# SAM9X75D1G device description
Architecture: ARM926EJ-S; Family: SAM9; Series: SAM9X7
Registers are 32-bit, read-write, reset 0x0 unless marked. A register's access mark holds for its fields unless they carry their own. Offsets are from the block's base; [hi:lo] are bit positions; {n}, {i} and the like mark numbered series.

## QSPI — Quad Serial Peripheral Interface
Instances: QSPI 0xF0014000
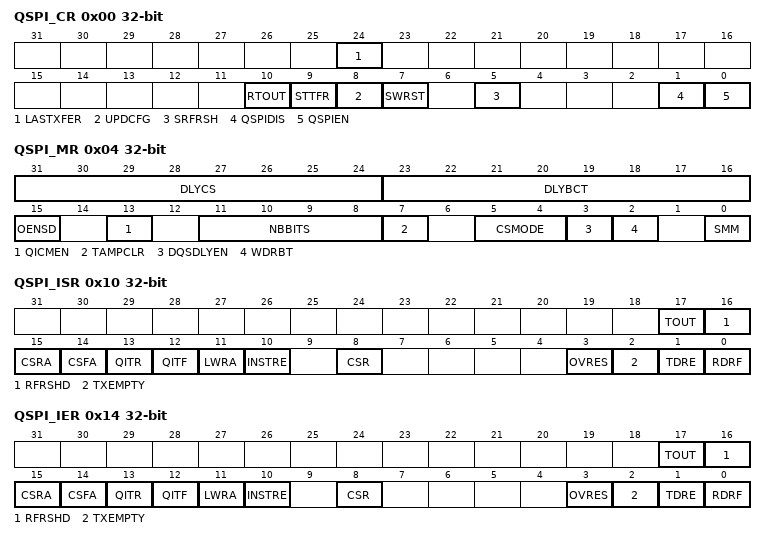
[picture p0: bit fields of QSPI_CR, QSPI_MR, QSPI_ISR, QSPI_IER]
0x00 QSPI_CR wo reset not defined — Control Register
  [24] LASTXFER — Last Transfer
    0=No effect; 1=The chip select is deasserted after the end of character transmission
  [10] RTOUT — Reset Time-out
    0=No effect; 1=Request a TOUT flag reset
  [9] STTFR — Start Transfer
    0=No effect; 1=Starts the transfer when TFRTYP = 0 and SMRM = 1 or when DATAEN = 0
  [8] UPDCFG — Update Configuration
    0=No effect; 1=Requests an update of the QSPI Controller core configuration
  [7] SWRST — QSPI Software Reset
    0=No effect; 1=Resets the QSPI. A software-triggered hardware reset of the QSPI interface is performed.
  [5] SRFRSH — Start REFRESH
    0=No effect; 1=Starts a refresh sequence. QSPI_ISR.RFRSHD indicates when the refresh sequence is over.
  [1] QSPIDIS — QSPI Disable
    0=No effect; 1=Disables the QSPI
  [0] QSPIEN — QSPI Enable
    0=No effect; 1=Enables the QSPI to transfer and receive data
0x04 QSPI_MR — Mode Register
  [31:24] DLYCS — Minimum Inactive QCS Delay
  [23:16] DLYBCT — Delay Between Consecutive Transfers
  [15] OENSD — Output Enable Shift Disabled
    0=By default, the pad output enable signal is held for one QSCK period during the dummy cycles if QSPI.IFR_NBDUM is not equal to '0'; 1=The pad output enable signal is not held for one QSCK period during the dummy cycles
  [13] QICMEN — QSPI Inter-chip Mode Enable
    0=DISABLED (QSPI_WICR.WROPT and QSPI_RICR.RDOPT define the transfer options and QSPI_IFR.NBDUM defines the number of dummy cycles.); 1=ENABLED (No dummy cycles are inserted for write accesses, whatever the value configured in QSPI_IFR.NBDUM. The option field of the frame is automatically generated by the QSPI depending on the type of system bus transfer (the fields QSPI_RICR.RDOPT and QSPI_WICR.WROPT have no effect).)
  [11:8] NBBITS — Number Of Bits Per Transfer
    0=8_BIT (8 bits for transfer); 8=16_BIT (16 bits for transfer)
  [7] TAMPCLR — Tamper Clear Enable
    0=A tamper detection event has no effect on QSPI scrambling keys; 1=A tamper detection event immediately clears QSPI scrambling keys
  [5:4] CSMODE — Chip Select Mode
    0=NOT_RELOADED (The chip select is deasserted if QSPI_TDR.TD has not been reloaded before the end of the current transfer.); 1=LASTXFER (The chip select is deasserted when the bit LASTXFER is written to '1' and the character written in QSPI_TDR.TD has been transferred.); 2=SYSTEMATICALLY (The chip select is deasserted systematically after each transfer.)
  [3] DQSDLYEN — DQS Delay Enable
    0=DISABLED (DQS Delay cell is disabled.); 1=ENABLED (DQS Delay cell is enabled. The DQS Delay cell automatic refresh is triggered according to the configuration of QSPI_REFRESH.)
  [2] WDRBT — Wait Data Read Before Transfer
    0=DISABLED (No effect. In SPI mode, a transfer can be initiated whatever the state of QSPI_RDR is.); 1=ENABLED (In SPI mode, a transfer can start only if QSPI_RDR is empty, i.e., does not contain any unread data. This mode prevents overrun error in reception.)
  [0] SMM — Serial Memory Mode
    0=SPI (The QSPI is in SPI mode.); 1=MEMORY (The QSPI is in Serial Memory mode.)
0x08 QSPI_RDR ro — Receive Data Register
  [15:0] RD — Receive Data
0x0C QSPI_TDR wo reset not defined — Transmit Data Register
  [15:0] TD — Transmit Data
0x10 QSPI_ISR ro — Interrupt Status Register
  [17] TOUT — QSPI Time-out
    0=No QSPI time-out occurred since the last write of RTOUT bit on QSPI_CR; 1=At least one QSPI time-out occurred since the last write of RTOUT bit on QSPI_CR
  [16] RFRSHD — Refresh Done
    0=No refresh done event occurred since the last read of QSPI_ISR; 1=One refresh done event has been detected since the end of the last refresh command or the last read of QSPI_ISR
  [15] CSRA — Chip Select Rise Autoclear
    0=No chip select rise has been detected since beginning of the last command or the last read of QSPI_ISR; 1=One chip select rise has been detected since the beginning of the last command or the last read of QSPI_ISR
  [14] CSFA — Chip Select Fall Autoclear
    0=No chip select fall has been detected since end of the last command or the last read of QSPI_ISR; 1=One chip select fall has been detected since the end of the last command or the last read of QSPI_ISR
  [13] QITR — QSPI Interrupt Rise
    0=No rising of the QSPI memory interrupt line has been detected since the last read of QSPI_ISR; 1=At least one QSPI memory interrupt line rising edge occurred since the last read of QSPI_ISR
  [12] QITF — QSPI Interrupt Fall
    0=No falling of the QSPI memory interrupt line has been detected since the last read of QSPI_ISR; 1=At least one QSPI memory interrupt line falling edge occurred since the last read of QSPI_ISR
  [11] LWRA — Last Write Access (cleared on read)
    0=Last write access has not been sent since the last read of QSPI_SR or NBWRA = 0; 1=At least one last write access has been sent since the last read of QSPI_SR
  [10] INSTRE — Instruction End Status (cleared on read)
    0=No instruction end has been detected since the last read of QSPI_SR; 1=At least one instruction end has been detected since the last read of QSPI_SR
  [8] CSR — Chip Select Rise (cleared on read)
    0=No chip select rise has been detected since the last read of QSPI_SR; 1=At least one chip select rise has been detected since the last read of QSPI_SR
  [3] OVRES — Overrun Error Status (cleared on read)
    0=No overrun has been detected since the last read of QSPI_ISR; 1=At least one overrun error has occurred since the last read of QSPI_ISR
  [2] TXEMPTY — Transmission Registers Empty (cleared by writing QSPI_TDR)
    0=As soon as data is written in QSPI_TDR; 1=QSPI_TDR and the internal shifter are empty. If a transfer delay has been defined, TXEMPTY is set after the completion of such delay.
  [1] TDRE — Transmit Data Register Empty (cleared by writing QSPI_TDR)
    0=Data has been written to QSPI_TDR and not yet transferred to the serializer; 1=The last data written in the QSPI_TDR has been transferred to the serializer
  [0] RDRF — Receive Data Register Full (cleared by reading QSPI_RDR)
    0=No data has been received since the last read of QSPI_RDR; 1=Data has been received and the received data has been transferred from the serializer to QSPI_RDR since the last read of QSPI_RDR
0x14 QSPI_IER wo reset not defined (atomic set of QSPI_IMR) — Interrupt Enable Register
  [17] TOUT — QSPI Time-out Interrupt Enable
  [16] RFRSHD — Refresh Done Interrupt Enable
  [15] CSRA — Chip Select Rise Autoclear Interrupt Enable
  [14] CSFA — Chip Select Fall Autoclear Interrupt Enable
  [13] QITR — QSPI Interrupt Rise Interrupt Enable
  [12] QITF — QSPI Interrupt Fall Interrupt Enable
  [11] LWRA — Last Write Access Interrupt Enable
  [10] INSTRE — Instruction End Interrupt Enable
  [8] CSR — Chip Select Rise Interrupt Enable
  [3] OVRES — Overrun Error Interrupt Enable
  [2] TXEMPTY — Transmission Registers Empty Enable
  [1] TDRE — Transmit Data Register Empty Interrupt Enable
  [0] RDRF — Receive Data Register Full Interrupt Enable
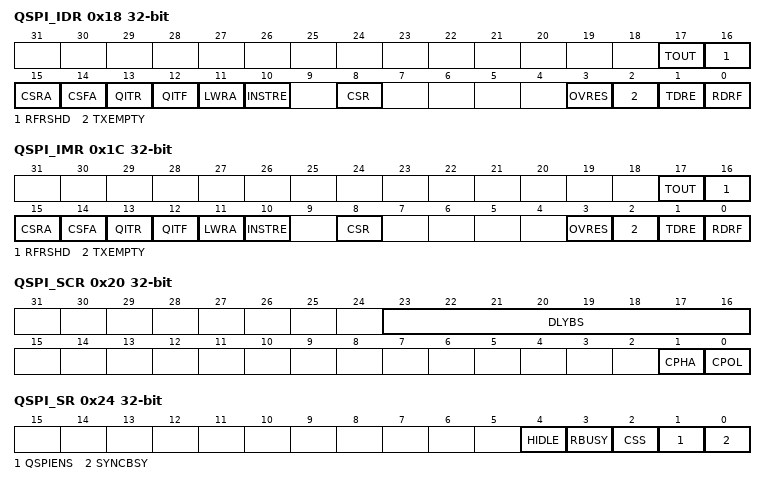
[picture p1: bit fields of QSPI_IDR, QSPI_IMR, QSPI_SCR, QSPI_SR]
0x18 QSPI_IDR wo reset not defined (atomic clear of QSPI_IMR) — Interrupt Disable Register
  [17] TOUT — QSPI Time-out Interrupt Disable
  [16] RFRSHD — Refresh Done Interrupt Disable
  [15] CSRA — Chip Select Rise Autoclear Interrupt Disable
  [14] CSFA — Chip Select Fall Autoclear Interrupt Disable
  [13] QITR — QSPI Interrupt Rise Interrupt Disable
  [12] QITF — QSPI Interrupt Fall Interrupt Disable
  [11] LWRA — Last Write Access Interrupt Disable
  [10] INSTRE — Instruction End Interrupt Disable
  [8] CSR — Chip Select Rise Interrupt Disable
  [3] OVRES — Overrun Error Interrupt Disable
  [2] TXEMPTY — Transmission Registers Empty Disable
  [1] TDRE — Transmit Data Register Empty Interrupt Disable
  [0] RDRF — Receive Data Register Full Interrupt Disable
0x1C QSPI_IMR ro — Interrupt Mask Register
  [17] TOUT — QSPI Time-out Interrupt Mask
  [16] RFRSHD — Refresh Done Interrupt Mask
  [15] CSRA — Chip Select Rise Autoclear Interrupt Mask
  [14] CSFA — Chip Select Fall Autoclear Interrupt Mask
  [13] QITR — QSPI Interrupt Rise Interrupt Mask
  [12] QITF — QSPI Interrupt Fall Interrupt Mask
  [11] LWRA — Last Write Access Interrupt Mask
  [10] INSTRE — Instruction End Interrupt Mask
  [8] CSR — Chip Select Rise Interrupt Mask
  [3] OVRES — Overrun Error Interrupt Mask
  [2] TXEMPTY — Transmission Registers Empty Mask
  [1] TDRE — Transmit Data Register Empty Interrupt Mask
  [0] RDRF — Receive Data Register Full Interrupt Mask
0x20 QSPI_SCR (atomic clear of QSPI_SR) — Serial Clock Register
  [23:16] DLYBS — Delay Before QSCK
  [1] CPHA — Clock Phase
    0=Data is captured on the leading edge of QSCK and changed on the following edge of QSCK; 1=Data is changed on the leading edge of QSCK and captured on the following edge of QSCK
  [0] CPOL — Clock Polarity
    0=The inactive state value of QSCK is logic level zero; 1=The inactive state value of QSCK is logic level one
0x24 QSPI_SR — Status Register
  [4] HIDLE — QSPI Idle
    0=The QSPI is not in Idle state (either transmitting or Chip Select is active); 1=The QSPI is in Idle state (not transmitting and Chip Select is inactive)
  [3] RBUSY — Read Busy
    0=The system bus interface has no activity; 1=The system bus interface is currently processing accesses
  [2] CSS — Chip Select Status
    0=The chip select is asserted; 1=The chip select is not asserted
  [1] QSPIENS — QSPI Enable Status
    0=The QSPI is disabled; 1=The QSPI is enabled
  [0] SYNCBSY — Synchronization Busy
    0=No event synchronization between the QSPI Controller interface and QSPI Controller core is ongoing. Register accesses requiring synchronization are allowed, see Register Synchronization.; 1=Event synchronization between the QSPI Controller interface and QSPI Controller core is ongoing. Register accesses requiring synchronization are not allowed, see Register Synchronization.
0x30 QSPI_IAR — Instruction Address Register
  [31:0] ADDR — Address
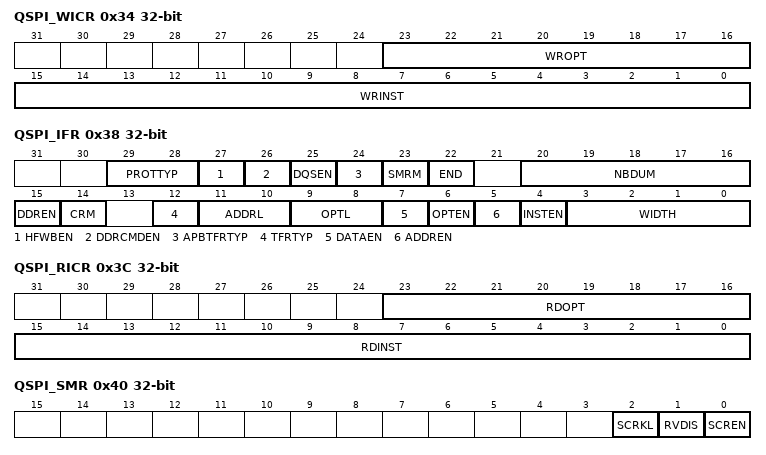
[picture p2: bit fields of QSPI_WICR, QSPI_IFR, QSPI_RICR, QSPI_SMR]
0x34 QSPI_WICR — Write Instruction Code Register
  [23:16] WROPT — Write Option Code
  [15:0] WRINST — Write Instruction Code
0x38 QSPI_IFR — Instruction Frame Register
  [29:28] PROTTYP — Protocol Type
    0=STD_SPI (Standard (Q)SPI Protocol); 1=TWIN_QUAD (Twin-Quad Protocol); 2=OCTAFLASH (OctaFlash Protocol); 3=HYPERFLASH (HyperFlash Protocol)
  [27] HFWBEN — HyperFlash Write Buffer Enable
    0=No effect; 1=Each write access received on the system bus interface generates a new command. IMPORTANT: Mandatory if HyperFlash Write Buffer feature is used.
  [26] DDRCMDEN — DDR Mode Command Enable
    0=DISABLED (Transfer of instruction field is performed in Single Data Rate mode even if DDREN is written to '1'.); 1=ENABLED (Transfer of instruction field is performed in Double Data Rate mode if DDREN bit is written to '1'. If DDREN is written to '0', the instruction field is sent in Single Data Rate mode.)
  [25] DQSEN — DQS Sampling Enable
    0=Data from the memory are not sampled with DQS signal; 1=Data from the memory are sampled with DQS signal
  [24] APBTFRTYP — Peripheral BusTransfer Type
    0=Peripheral bus register transfer to the memory is a write transfer. Used when TRFTYP is written to '0' and SMRM to '1'.; 1=Peripheral bus register transfer to the memory is a read transfer. Used when TRFTYP is written to '0' and SMRM to '1'.
  [23] SMRM — Serial Memory Register Mode
    0=Serial Memory registers are written via AHB access. See Instruction Frame Transmission for details.; 1=Serial Memory registers are written via APB access. See Instruction Frame Transmission for details.
  [22] END — Endianness
    0=Data are sent in little-endian format to the memory; 1=Data are sent in big-endian format to the memory
  [20:16] NBDUM — Number Of Dummy Cycles
  [15] DDREN — DDR Mode Enable
    0=DISABLED (Transfers are performed in Single Data Rate mode.); 1=ENABLED (Transfers are performed in Double Data Rate mode, whereas the instruction field is still transferred in Single Data Rate mode.)
  [14] CRM — Continuous Read Mode
    0=DISABLED (Continuous Read mode is disabled.); 1=ENABLED (Continuous Read mode is enabled.)
  [12] TFRTYP — Data Transfer Type
    0=TRSFR_REGISTER (Read/Write of memory register, write of memory page buffer. This configuration implies the following: Either the AHB or the APB interface can be used to initiate the transfer (SMRM bit). Returned data represents the memory register value. If the APB interface is used, the RDRF and TDRE flags help to control the frame. Scrambling is possible only if the APB interface is used. For HyperFlash memories the "target" bit is set to register space in the HyperFlash header.); 1=TRSFR_MEMORY (Read/Write accesses to the memory space. This configuration implies the following: Only the System Bus interface can be used to trigger accesses. Access to random location is possible. Address mask is applied and full size accesses only are performed. Internal optimization algorithm is enabled to minimize latency. Data are returned in a system bus protocol compliant way. Seamless scrambling is enabled. Seamless handling of HyperFlash Write Buffer programming command (one command for each data) Seamless protocol-specific page boundary handling Address shift is handled seamlessly (e.g. halfword memories).)
  [11:10] ADDRL — Address Length
    0=8_BIT (8-bit address size); 1=16_BIT (16-bit address size); 2=24_BIT (24-bit address size); 3=32_BIT (32-bit address size)
  [9:8] OPTL — Option Code Length
    0=OPTION_1BIT (The option code is 1 bit long.); 1=OPTION_2BIT (The option code is 2 bits long.); 2=OPTION_4BIT (The option code is 4 bits long.); 3=OPTION_8BIT (The option code is 8 bits long.)
  [7] DATAEN — Data Enable
    0=No data is sent/received to/from the serial Flash memory; 1=Data is sent/received to/from the serial Flash memory
  [6] OPTEN — Option Enable
    0=The option is not sent to the serial Flash memory; 1=The option is sent to the serial Flash memory
  [5] ADDREN — Address Enable
    0=The transfer address is not sent to the serial Flash memory; 1=The transfer address is sent to the serial Flash memory
  [4] INSTEN — Instruction Enable
    0=The instruction is not sent to the serial Flash memory; 1=The instruction is sent to the serial Flash memory
  [3:0] WIDTH — Width of Instruction Code, Address, Option Code and Data
    0=SINGLE_BIT_SPI (Instruction: Single-bit SPI / Address-Option: Single-bit SPI / Data: Single-bit SPI); 1=DUAL_OUTPUT (Instruction: Single-bit SPI / Address-Option: Single-bit SPI / Data: Dual SPI); 2=QUAD_OUTPUT (Instruction: Single-bit SPI / Address-Option: Single-bit SPI / Data: Quad SPI); 3=DUAL_IO (Instruction: Single-bit SPI / Address-Option: Dual SPI / Data: Dual SPI); 4=QUAD_IO (Instruction: Single-bit SPI / Address-Option: Quad SPI / Data: Quad SPI); 5=DUAL_CMD (Instruction: Dual SPI / Address-Option: Dual SPI / Data: Dual SPI); 6=QUAD_CMD (Instruction: Quad SPI / Address-Option: Quad SPI / Data: Quad SPI); 7=OCT_OUTPUT (Instruction: Single-bit SPI / Address-Option: Single-bit SPI / Data: Octal SPI); 8=OCT_IO (Instruction: Single-bit SPI / Address-Option: Octal SPI / Data: Octal SPI); 9=OCT_CMD (Instruction: Octal SPI / Address-Option: Octal SPI / Data: Octal SPI)
0x3C QSPI_RICR — Read Instruction Code Register
  [23:16] RDOPT — Read Option Code
  [15:0] RDINST — Read Instruction Code
0x40 QSPI_SMR — Scrambling Mode Register
  [2] SCRKL — Scrambling Key Lock
    0=No action; 1=QSPI_SKR.USRK cannot be written until the next VDDCORE reset
  [1] RVDIS — Scrambling/Unscrambling Random Value Disable
    0=The scrambling/unscrambling algorithm includes the user scrambling key plus a random value that may differ between devices; 1=The scrambling/unscrambling algorithm includes only the user scrambling key
  [0] SCREN — Scrambling/Unscrambling Enable
    0=DISABLED (The scrambling/unscrambling is disabled.); 1=ENABLED (The scrambling/unscrambling is enabled.)
0x44 QSPI_SKR wo reset not defined — Scrambling Key Register
  [31:0] USRK — User Scrambling Key
0x50 QSPI_REFRESH — Refresh Register
  [31:0] REFRESH — REFRESH Delay Counter
0x54 QSPI_WRACNT — Write Access Counter Register
  [31:0] NBWRA — Number of Write Accesses
0x5C QSPI_PCALCFG reset 0x70 — Pad Calibration Configuration Register
  [2] DIFFPM — Differential Pad Mode
    0=Pad differential mode is not enabled; 1=Pad differential mode is enabled
0x64 QSPI_TOUT — Timeout Register
  [15:0] TCNTM — Time-out Counter Maximum Value
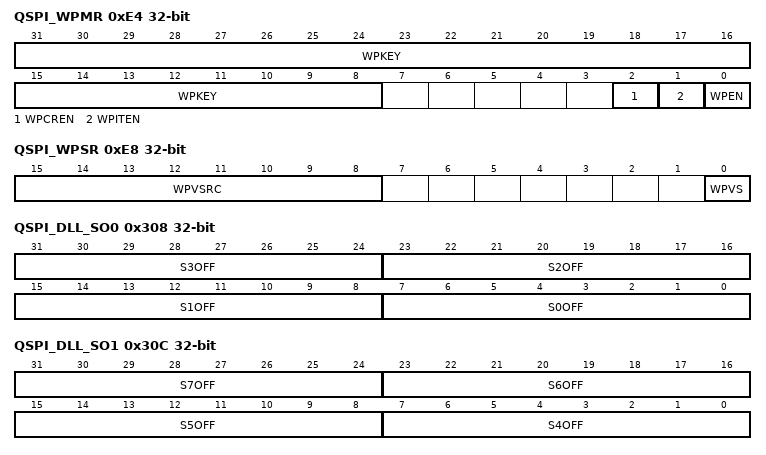
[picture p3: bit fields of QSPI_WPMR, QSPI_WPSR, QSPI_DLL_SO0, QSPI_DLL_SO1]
0xE4 QSPI_WPMR — Write Protection Mode Register
  [31:8] WPKEY — Write Protection Key
    0x515350=PASSWD (Writing any other value in this field aborts the write operation of the WPEN bit. Always reads as 0.)
  [2] WPCREN — Write Protection Control Register Enable
    0=Disables the write protection on the Control register if WPKEY corresponds to 0x515350; 1=Enables the write protection on the Control register if WPKEY corresponds to 0x515350
  [1] WPITEN — Write Protection Interrupt Enable
    0=Disables the write protection on Interrupt registers if WPKEY corresponds to 0x515350; 1=Enables the write protection on Interrupt registers if WPKEY corresponds to 0x515350
  [0] WPEN — Write Protection Enable
    0=Disables the write protection if WPKEY corresponds to 0x515350 ("QSP" in ASCII); 1=Enables the write protection if WPKEY corresponds to 0x515350 ("QSP" in ASCII)
0xE8 QSPI_WPSR ro — Write Protection Status Register
  [15:8] WPVSRC — Write Protection Violation Source
  [0] WPVS — Write Protection Violation Status
    0=No write protection violation has occurred since the last read of the QSPI_WPSR; 1=A write protection violation has occurred since the last read of the QSPI_WPSR. If this violation is an unauthorized attempt to write a protected register, the associated violation is reported into field WPVSRC.
0x300 QSPI_DLL_OS — QSPI DLL Offset Selection Register
  [0] SELOFF — Offset Selection
    0=The hardcoded offsets are selected; 1=The programmable offsets are selected
0x304 QSPI_DLL_MAO — QSPI DLL Host Offset Register
  [7:0] MAOFF — Host Delay Line Offset
0x308 QSPI_DLL_SO0 — QSPI DLL Client Offset 0 Register
  [8n+7:8n] S{n}OFF (n=0..3) — SLAVEx Delay Line Offset
0x30C QSPI_DLL_SO1 — QSPI DLL Client Offset 1 Register
  [8n-25:8n-32] S{n}OFF (n=4..7) — SLAVEx Delay Line Offset
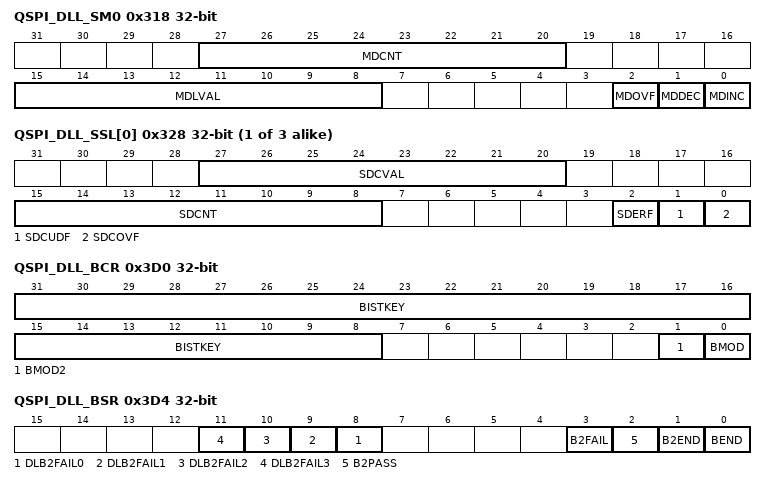
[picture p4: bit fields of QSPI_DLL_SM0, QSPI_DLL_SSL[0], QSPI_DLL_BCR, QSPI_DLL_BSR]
0x318 QSPI_DLL_SM0 ro — QSPI DLL Status Host 0 Register
  [27:20] MDCNT — MASTER0 Delay Counter Value
  [15:8] MDLVAL — MASTER0 Delay Lock Value
  [2] MDOVF — MASTER0 Delay Overflow Flag
    0=The MASTER0 delay counter has not reached its maximum value, or MASTER0 is not locked yet; 1=The MASTER0 delay counter has reached its maximum value, the MASTER0 delay counter increment is stopped and the DQSDELAY forces the MASTER0 clock. If this flag is set, it means the DDR-SDRAM controller clock frequency is too low compared to MASTER0 delay line number of elements.
  [1] MDDEC — MASTER0 Delay Decrement
    0=The DQSDELAY is not decrementing the MASTER0 delay counter; 1=The DQSDELAY is decrementing the MASTER0 delay counter
  [0] MDINC — MASTER0 Delay Increment
    0=The DQSDELAY is not incrementing the MASTER0 delay counter; 1=The DQSDELAY is incrementing the MASTER0 delay counter
{0x328+4i} QSPI_DLL_SSL[{i}] (i=0..2) ro — QSPI DLL Status Client x Register
  [27:20] SDCVAL — SLAVE0 Delay Correction Value
  [15:8] SDCNT — SLAVE0 Delay Counter Value
  [2] SDERF — SLAVE0 Delay Correction Error Flag
    0=The DQSDELAY has succeeded in computing the SLAVE0 delay correction, or the client is not locked yet; 1=The DQSDELAY has not succeeded in computing the SLAVE0 delay correction
  [1] SDCUDF — SLAVE0 Delay Correction Underflow Flag
    0=Due to the correction, the SLAVE0 delay counter has not reached its minimum value, or SLAVE0 is not locked yet; 1=Due to the correction, the SLAVE0 delay counter has reached its minimum value. The correction is not optimal because it has not been applied entirely.
  [0] SDCOVF — SLAVE0 Delay Correction Overflow Flag
    0=Due to the correction, the SLAVE0 delay counter has not reached its maximum value, or SLAVE0 is not locked yet; 1=Due to the correction, the SLAVE0 delay counter has reached its maximum value. The correction is not optimal because it is not applied entirely.
0x3D0 QSPI_DLL_BCR — QSPI DLL BIST Control Register
  [31:8] BISTKEY
    0xDD3313=VALUE (Write to 0xDD3313 to enable modification of BMOD or BMOD2 state.)
  [1] BMOD2 — BIST Mode 2
  [0] BMOD — BIST Mode
0x3D4 QSPI_DLL_BSR ro — QSPI DLL BIST Status Register
  [n+8] DLB2FAIL{n} (n=0..3) — Delay Line BIST 2 Fail for Delay Line {n}
    0=The BIST 2 test did not fail; 1=The BIST 2 test failed for delay line x
  [3] B2FAIL — BIST 2 Fail
    0=The BIST 2 test has not finished or succeeded; 1=The BIST 2 test failed. Check DLB2FAILx bits to identify the corrupted delay lines.
  [2] B2PASS — BIST 2 Pass
    0=The BIST 2 test has not finished or failed; 1=The BIST 2 test ended successfully
  [1] B2END — BIST 2 End
    0=BIST 2 test has not started or in progress; 1=BIST 2 test is finished
  [0] BEND — BIST End
    0=BIST test has not started or is in progress; 1=BIST test is finished
0x3E0 QSPI_DLL_SYNCR — QSPI DLL Synchro Register
  [0] UPDT — Update configuration
    0=No effect; 0=Configuration is up to date; 1=Initiates the configuration update; 1=Configuration is being updated
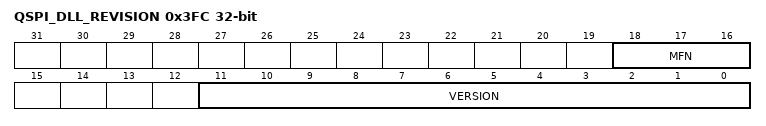
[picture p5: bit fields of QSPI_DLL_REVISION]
0x3FC QSPI_DLL_REVISION ro — QSPI DQSDELAY Revision Register
  [18:16] MFN — Metal Fix Number
  [11:0] VERSION — Hardware Module Version

## Notices in the file
Copyright (c) 2021 Microchip Technology Inc.
SPDX-License-Identifier: Apache-2.0
Licensed under the Apache License, Version 2.0 (the "License");
you may not use this file except in compliance with the License.
You may obtain a copy of the License at
http://www.apache.org/licenses/LICENSE-2.0
Unless required by applicable law or agreed to in writing, software
distributed under the License is distributed on an "AS IS" BASIS,
WITHOUT WARRANTIES OR CONDITIONS OF ANY KIND, either express or implied.
See the License for the specific language governing permissions and
limitations under the License.
